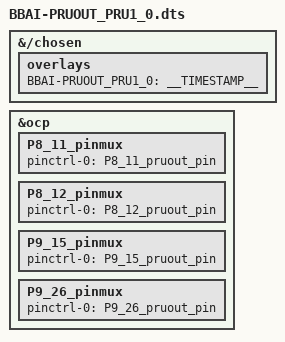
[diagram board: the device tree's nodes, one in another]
/*
 * Copyright (C) 2020 Deepak Khatri <deepaklorkhatri7@gmail.com>
 * See Cape Interface Spec page for more info on Bone Buses
 * https://elinux.org/Beagleboard:BeagleBone_cape_interface_spec
 *
 * Virtual cape for pr1_pru0_gpo* pins
 *
 * This program is free software; you can redistribute it and/or modify
 * it under the terms of the GNU General Public License version 2 as
 * published by the Free Software Foundation.
 */
/dts-v1/;
/plugin/;

/*
* Helper to show loaded overlays under: /proc/device-tree/chosen/overlays/
*/
&{/chosen} {
    overlays {
        BBAI-PRUOUT_PRU1_0 = __TIMESTAMP__;
    };
};

/*
 * Update the default pinmux of the pins.
 * See these files for the phandles (&P9_* & &P8_*)
 * BeagleBoard-DeviceTrees/v4.19.x-ti-overlays/src/arm/am335x-bone-common-univ.dtsi
 * BeagleBoard-DeviceTrees/v4.19.x-ti-overlays/src/arm/am572x-bone-common-univ.dtsi
 */
&ocp {
    P8_11_pinmux { pinctrl-0 = <&P8_11_pruout_pin>; }; /* pr1_pru0_gpo4 */
    P8_12_pinmux { pinctrl-0 = <&P8_12_pruout_pin>; }; /* pr1_pru0_gpo3 */

    P9_15_pinmux { pinctrl-0 = <&P9_15_pruout_pin>; }; /* pr1_pru0_gpo5 */
    P9_26_pinmux { pinctrl-0 = <&P9_26_pruout_pin>; }; /* pr1_pru0_gpo17 */
};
